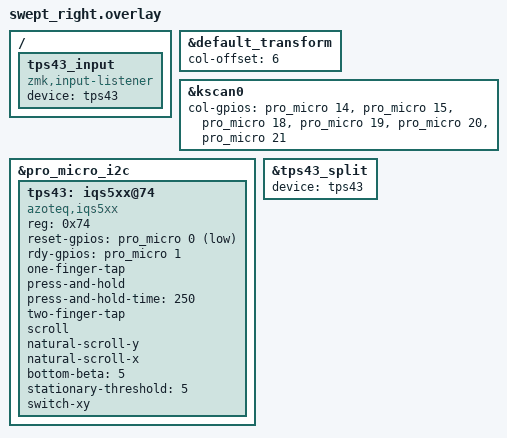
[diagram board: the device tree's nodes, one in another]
/*
 * Copyright (c) 2020 The ZMK Contributors
 *
 * SPDX-License-Identifier: MIT
 */

#include "swept.dtsi"

&default_transform {
	col-offset = <6>;
};

&kscan0 {
	col-gpios
		= <&pro_micro 14 GPIO_ACTIVE_HIGH>
		, <&pro_micro 15 GPIO_ACTIVE_HIGH>
		, <&pro_micro 18 GPIO_ACTIVE_HIGH>
		, <&pro_micro 19 GPIO_ACTIVE_HIGH>
		, <&pro_micro 20 GPIO_ACTIVE_HIGH>
		, <&pro_micro 21 GPIO_ACTIVE_HIGH>
		;
};

&pro_micro_i2c {
    status = "okay";
    tps43: iqs5xx@74 {
        status = "okay";
        compatible = "azoteq,iqs5xx";
        reg = <0x74>;

        reset-gpios = <&pro_micro 0 GPIO_ACTIVE_LOW>;
        rdy-gpios = <&pro_micro 1 GPIO_ACTIVE_HIGH>;

        /*
         * Potentially non-exhaustive list of configuration options.
         * See: dts/bindings/input/azoteq,iqs5xx-common.yaml for a full list.
         */
        one-finger-tap;
        press-and-hold;
        press-and-hold-time = <250>;
        two-finger-tap;

        scroll;
        natural-scroll-y;
        natural-scroll-x;

        bottom-beta = <5>;
        stationary-threshold = <5>;

        switch-xy;
    };
};

/ {
    tps43_input: tps43_input {
        compatible = "zmk,input-listener";
        device = <&tps43>;
    };
};

&tps43_split {
    device = <&tps43>;
};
